# SYSC register map
Vendor: Texas Instruments
Peripheral module from a debugger description file (folder omap34xx).
Registers are 32-bit, read-only, reset 0x0 unless marked. A register's access mark holds for its fields unless they carry their own. Offsets are as the file gives them; lines under a group give offsets from that group; [hi:lo] are bit positions; {n}, {i} and the like mark numbered series; 'fields as' and 'values as' point back to an identical list; <NAME> marks a mode.

## SYSC
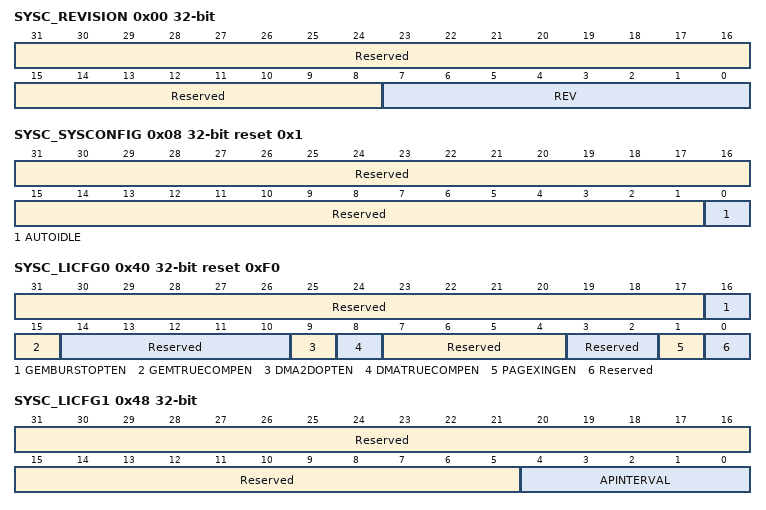
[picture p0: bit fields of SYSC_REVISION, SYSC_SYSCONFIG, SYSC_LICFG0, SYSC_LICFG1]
0x00 SYSC_REVISION (reset mask 0xFFFFFF00) — This register contains the IP revision code
  [31:8] Reserved — Read returns 0.
  [7:0] REV — IP revision3:0 Minor revision7:4 Major revision
0x08 SYSC_SYSCONFIG rw reset 0x1 — This register allows controlling various parameters of the SYSC module
  [31:1] Reserved — Write 0s for future compatibility.Read returns 0.
  [0] AUTOIDLE — Internal auto-clock gating strategy0: Clock is free running1: Automatic clock gating strategy is applied
0x40 SYSC_LICFG0 rw reset 0xF0 — This register controls various parameters of the IVA2.2 local interconnect network
  [31:17] Reserved — Write 0s for future compatibility.Read returns 0.
  [16] GEMBURSTOPTEN — DSP megamodule cache-line operation transfers optimizationcontrol:0: DSP megamodule cache operation transfers are not optimized1: DSP megamodule cache operation transfers are optimized
  [15] GEMTRUECOMPEN — DSP megamodule program-initiated write-back transfer true completion control:0: DSP megamodule program-initiated write-back transfer completion is not accurate1: DSP megamodule program initiated write-back transfer completion is accurate
  [14:10] Reserved — Write 0s for future compatibility.Read returns 0.
  [9] DMA2DOPTEN — 2D transfers optimization control:0: 2D DMA transfers optimization is disabled1: 2D DMA transfers optimization is enabled
  [8] DMATRUECOMPEN — DMA write transfer true completion control:0: DMA write transfer completion is not accurate1: DMA write transfer completion is accurate
  [7:4] Reserved — Write 0xF for compatibilityRead returns 0xF
  [3:2] Reserved — Write 0s for future compatibility.Read returns 0.
  [1] PAGEXINGEN — MMU page crossing enable:0: Bursts are not allowed to cross 4KB page boundaries1: Bursts are allowed to cross 4KB page boundaries
  [0] Reserved — Write 0s for future compatibility.Read returns 0.
0x48 SYSC_LICFG1 rw — This register allows controlling various parameters of the IVA2.2 local interconnect network
  [31:5] Reserved — Write 0s for future compatibility.Read returns 0.
  [4:0] APINTERVAL — Control of the Aged Priority (priority inversion) for DMA accesses:When set to 0x0, the aged priority is disabled . When set to another value, this controls how often the priority is adjusted: every APInterval cycles, the priority of the port is decreased until the associated request is accepted or the priority of the port equals 0. The priority of the port is reinitialized to the transaction priority each time a new VBUS command is generated, i.e. the last one has been accepted. . There is no aged priority in SCR. DMA transaction keeps the fixed priority defined internally, and has to wait for the bus to be freed by higher priority initiators .
    0=Aged Priority Disabled:
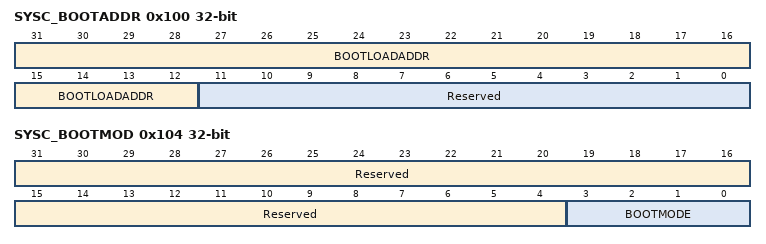
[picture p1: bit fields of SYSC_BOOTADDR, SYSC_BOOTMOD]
0x100 SYSC_BOOTADDR (reset mask 0xFFF) — This register defines the physical address of the IVA2 boot loader. This is a copy of the CONTROL_IVA2_BOOTADDR when the IVA2 is released from reset.
  [31:12] BOOTLOADADDR — Physical address of the IVA2 boot loader:This is the read-only copy of the CONTROL_IVA2_BOOTADDR when the IVA2 is released fromresetThis is an index to a 4K-byte page
  [11:0] Reserved — Read returns 0.
0x104 SYSC_BOOTMOD (reset mask 0xFFFFFFF0) — This register defines the IVA2 boot mode. This is a copy of the CONTROL_IVA2_BOOTMOD when the IVA2 is released from reset.
  [31:4] Reserved — Read returns 0.
  [3:0] BOOTMODE — Boot mode of the IVA2:This is the read-only copy of the IVA2_BOOTMOD when the IVA2 is released from resetThe value meaning is defined by the IVA2 ROM boot code
